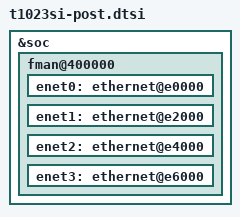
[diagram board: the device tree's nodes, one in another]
// SPDX-License-Identifier: (GPL-2.0+ OR BSD-3-Clause)
/*
 * T1023 Silicon/SoC Device Tree Source (post include)
 *
 * Copyright 2014 Freescale Semiconductor Inc.
 * Copyright 2019-2023 NXP
 *
 */

&soc {

/include/ "qoriq-clockgen2.dtsi"
/include/ "qoriq-duart-0.dtsi"
/include/ "qoriq-duart-1.dtsi"
/include/ "qoriq-gpio-0.dtsi"
/include/ "qoriq-gpio-1.dtsi"
/include/ "qoriq-gpio-2.dtsi"
/include/ "qoriq-gpio-3.dtsi"
/include/ "qoriq-sec5.0-0.dtsi"

/* include used FMan blocks */
/include/ "qoriq-fman3l-0.dtsi"
/include/ "qoriq-fman3-0-10g-0-best-effort.dtsi"
/include/ "qoriq-fman3-0-1g-1.dtsi"
/include/ "qoriq-fman3-0-1g-2.dtsi"
/include/ "qoriq-fman3-0-1g-3.dtsi"
	fman@400000 {
		enet0: ethernet@e0000 {
		};

		enet1: ethernet@e2000 {
		};

		enet2: ethernet@e4000 {
		};

		enet3: ethernet@e6000 {
		};
	};
};
